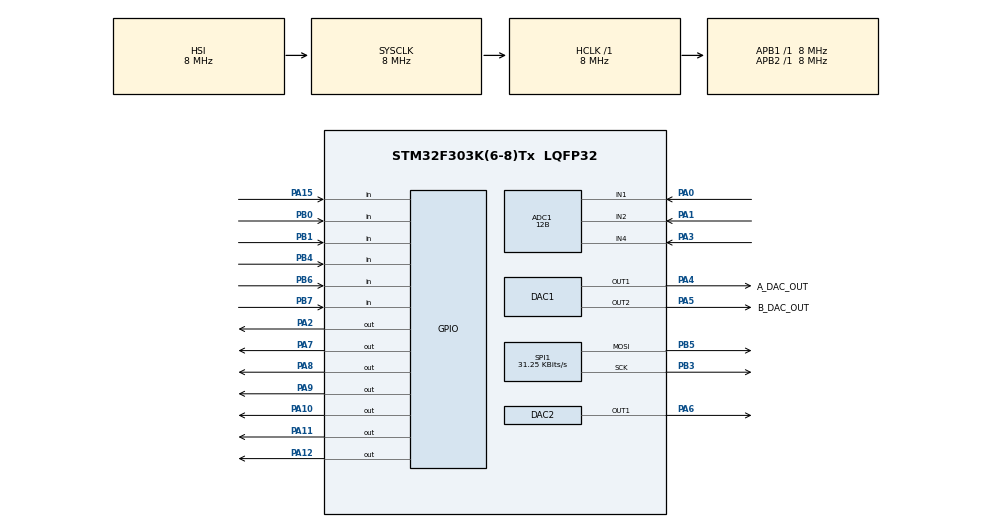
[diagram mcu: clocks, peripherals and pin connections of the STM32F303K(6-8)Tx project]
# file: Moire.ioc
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ADC1.Channel-17\#ChannelRegularConversion=ADC_CHANNEL_1
ADC1.Channel-18\#ChannelRegularConversion=ADC_CHANNEL_2
ADC1.Channel-19\#ChannelRegularConversion=ADC_CHANNEL_4
ADC1.Channel-21\#ChannelRegularConversion=ADC_CHANNEL_4
ADC1.ClockPrescaler=ADC_CLOCK_SYNC_PCLK_DIV4
ADC1.ContinuousConvMode=ENABLE
ADC1.DMAContinuousRequests=ENABLE
ADC1.DataAlign=ADC_DATAALIGN_RIGHT
ADC1.DiscontinuousConvMode=DISABLE
ADC1.EOCSelection=ADC_EOC_SEQ_CONV
ADC1.EnableAnalogWatchDog1=false
ADC1.EnableAnalogWatchDog2=false
ADC1.EnableAnalogWatchDog3=false
ADC1.EnableInjectedConversion=ENABLE
ADC1.EnableRegularConversion=ENABLE
ADC1.ExternalTrigConv=ADC_SOFTWARE_START
ADC1.ExternalTrigConvEdge=ADC_EXTERNALTRIGCONVEDGE_NONE
ADC1.InjNumberOfConversion=0
ADC1.LowPowerAutoWait=DISABLE
ADC1.NbrOfConversion=4
ADC1.NbrOfConversionFlag=1
ADC1.Offset-17\#ChannelRegularConversion=0
ADC1.Offset-18\#ChannelRegularConversion=0
ADC1.Offset-19\#ChannelRegularConversion=0
ADC1.Offset-21\#ChannelRegularConversion=0
ADC1.OffsetNumber-17\#ChannelRegularConversion=ADC_OFFSET_NONE
ADC1.OffsetNumber-18\#ChannelRegularConversion=ADC_OFFSET_NONE
ADC1.OffsetNumber-19\#ChannelRegularConversion=ADC_OFFSET_NONE
ADC1.OffsetNumber-21\#ChannelRegularConversion=ADC_OFFSET_NONE
ADC1.Overrun=ADC_OVR_DATA_OVERWRITTEN
ADC1.Rank-17\#ChannelRegularConversion=1
ADC1.Rank-18\#ChannelRegularConversion=2
ADC1.Rank-19\#ChannelRegularConversion=3
ADC1.Rank-21\#ChannelRegularConversion=4
ADC1.Resolution=ADC_RESOLUTION_12B
ADC1.SamplingTime-17\#ChannelRegularConversion=ADC_SAMPLETIME_1CYCLE_5
ADC1.SamplingTime-18\#ChannelRegularConversion=ADC_SAMPLETIME_1CYCLE_5
ADC1.SamplingTime-19\#ChannelRegularConversion=ADC_SAMPLETIME_1CYCLE_5
ADC1.SamplingTime-21\#ChannelRegularConversion=ADC_SAMPLETIME_1CYCLE_5
ADC1.ScanConvMode=ADC_SCAN_ENABLE
ADC1.SubFamily=STM32F303x8
ADC1.master=1
DAC1.DAC_OutputBuffer=DAC_OUTPUTBUFFER_ENABLE
DAC1.DAC_Trigger=DAC_TRIGGER_NONE
Dma.ADC1.1.Direction=DMA_PERIPH_TO_MEMORY
Dma.ADC1.1.Instance=DMA1_Channel1
Dma.ADC1.1.MemDataAlignment=DMA_MDATAALIGN_WORD
Dma.ADC1.1.MemInc=DMA_MINC_ENABLE
Dma.ADC1.1.Mode=DMA_CIRCULAR
Dma.ADC1.1.PeriphDataAlignment=DMA_PDATAALIGN_WORD
Dma.ADC1.1.PeriphInc=DMA_PINC_DISABLE
Dma.ADC1.1.Priority=DMA_PRIORITY_LOW
Dma.DAC1_CH1.0.Direction=DMA_MEMORY_TO_PERIPH
Dma.DAC1_CH1.0.Instance=DMA1_Channel3
Dma.DAC1_CH1.0.MemDataAlignment=DMA_MDATAALIGN_HALFWORD
Dma.DAC1_CH1.0.MemInc=DMA_MINC_ENABLE
Dma.DAC1_CH1.0.Mode=DMA_CIRCULAR
Dma.DAC1_CH1.0.PeriphDataAlignment=DMA_PDATAALIGN_HALFWORD
Dma.DAC1_CH1.0.PeriphInc=DMA_PINC_DISABLE
Dma.DAC1_CH1.0.Priority=DMA_PRIORITY_HIGH
Dma.Request0=DAC1_CH1
Dma.Request1=ADC1
Mcu.Family=STM32F3
Mcu.Name=STM32F303K(6-8)Tx
Mcu.Package=LQFP32
NVIC.ADC1_2_IRQn=true\:0\:0\:false\:false\:true\:true
NVIC.DMA1_Channel1_IRQn=true\:0\:0\:false\:false\:true\:false
NVIC.DMA1_Channel3_IRQn=true\:0\:0\:false\:false\:true\:false
NVIC.PriorityGroup=NVIC_PRIORITYGROUP_4
NVIC.TIM2_IRQn=true\:0\:0\:false\:false\:true\:true
NVIC.TIM6_DAC1_IRQn=true\:0\:0\:false\:false\:true\:true
PA0.Mode=IN1-Single-Ended
PA0.Signal=ADC1_IN1
PA1.Mode=IN2-Single-Ended
PA1.Signal=ADC1_IN2
PA10.Signal=GPIO_Output
PA11.Signal=GPIO_Output
PA12.Signal=GPIO_Output
PA13.GPIO_Label=SWDIO
PA13.Signal=SYS_JTMS-SWDIO
PA14.Signal=SYS_JTCK-SWCLK
PA15.GPIO_PuPd=GPIO_PULLUP
PA15.Signal=GPIO_Input
PA2.Signal=GPIO_Output
PA3.Mode=IN4-Single-Ended
PA3.Signal=ADC1_IN4
PA4.GPIO_Label=A_DAC_OUT
PA4.Signal=COMP_DAC11_group
PA5.GPIO_Label=B_DAC_OUT
PA5.Signal=COMP_DAC12_group
PA6.Signal=COMP_DAC21_group
PA7.Signal=GPIO_Output
PA8.Signal=GPIO_Output
PA9.GPIO_Speed=GPIO_SPEED_FREQ_HIGH
PA9.PinState=GPIO_PIN_RESET
PA9.Signal=GPIO_Output
PB0.GPIO_PuPd=GPIO_PULLUP
PB0.Signal=GPIO_Input
PB1.GPIO_PuPd=GPIO_PULLUP
PB1.Signal=GPIO_Input
PB3.Mode=TX_Only_Simplex_Unidirect_Master
PB3.Signal=SPI1_SCK
PB4.GPIO_PuPd=GPIO_PULLUP
PB4.Signal=GPIO_Input
PB5.Mode=TX_Only_Simplex_Unidirect_Master
PB5.Signal=SPI1_MOSI
PB6.GPIO_PuPd=GPIO_PULLUP
PB6.Signal=GPIO_Input
PB7.GPIO_PuPd=GPIO_PULLUP
PB7.Signal=GPIO_Input
PF0\ /\ OSC_IN.Mode=HSE-External-Oscillator
PF0\ /\ OSC_IN.Signal=RCC_OSC_IN
PF1\ /\ OSC_OUT.Mode=HSE-External-Oscillator
PF1\ /\ OSC_OUT.Signal=RCC_OSC_OUT
ProjectManager.HeapSize=0x200
ProjectManager.StackSize=0x400
ProjectManager.TargetToolchain=Makefile
RCC.AHBFreq_Value=8000000
RCC.APB1Freq_Value=8000000
RCC.APB2Freq_Value=8000000
RCC.CortexFreq_Value=8000000
RCC.HSE_VALUE=8000000
RCC.HSI_VALUE=8000000
RCC.PLLMUL=RCC_PLL_MUL4
RCC.SYSCLKFreq_VALUE=8000000
SH.COMP_DAC11_group.0=DAC1_OUT1,DAC_OUT1
SH.COMP_DAC12_group.0=DAC1_OUT2,DAC_OUT2
SH.COMP_DAC21_group.0=DAC2_OUT1,Switch_Enable_OUT1
SPI1.BaudRatePrescaler=SPI_BAUDRATEPRESCALER_256
SPI1.CLKPolarity=SPI_POLARITY_LOW
SPI1.CalculateBaudRate=31.25 KBits/s
SPI1.DataSize=SPI_DATASIZE_16BIT
SPI1.Direction=SPI_DIRECTION_2LINES
SPI1.Mode=SPI_MODE_MASTER
SPI1.NSSPMode=SPI_NSS_PULSE_ENABLE
SPI1.VirtualType=VM_MASTER
TIM2.Period=4608
TIM2.Prescaler=1
TIM6.Period=1
TIM6.Prescaler=1
TIM6.TIM_MasterOutputTrigger=TIM_TRGO_UPDATE
VP_TIM2_VS_ClockSourceINT.Mode=Internal
VP_TIM6_VS_ClockSourceINT.Mode=Enable_Timer
VP_TIM7_VS_ClockSourceINT.Mode=Enable_Timer
board=NUCLEO-F303K8

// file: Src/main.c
/**
  ******************************************************************************
  * @file           : main.c
  * @brief          : Main program body
  ******************************************************************************
  ** This notice applies to any and all portions of this file
  * that are not between comment pairs USER CODE BEGIN and
  * USER CODE END. Other portions of this file, whether
  * inserted by the user or by software development tools
  * are owned by their respective copyright owners.
  *
  * COPYRIGHT(c) 2018 STMicroelectronics
  *
  * Redistribution and use in source and binary forms, with or without modification,
  * are permitted provided that the following conditions are met:
  *   1. Redistributions of source code must retain the above copyright notice,
  *      this list of conditions and the following disclaimer.
  *   2. Redistributions in binary form must reproduce the above copyright notice,
  *      this list of conditions and the following disclaimer in the documentation
  *      and/or other materials provided with the distribution.
  *   3. Neither the name of STMicroelectronics nor the names of its contributors
  *      may be used to endorse or promote products derived from this software
  *      without specific prior written permission.
  *
  * THIS SOFTWARE IS PROVIDED BY THE COPYRIGHT HOLDERS AND CONTRIBUTORS "AS IS"
  * AND ANY EXPRESS OR IMPLIED WARRANTIES, INCLUDING, BUT NOT LIMITED TO, THE
  * IMPLIED WARRANTIES OF MERCHANTABILITY AND FITNESS FOR A PARTICULAR PURPOSE ARE
  * DISCLAIMED. IN NO EVENT SHALL THE COPYRIGHT HOLDER OR CONTRIBUTORS BE LIABLE
  * FOR ANY DIRECT, INDIRECT, INCIDENTAL, SPECIAL, EXEMPLARY, OR CONSEQUENTIAL
  * DAMAGES (INCLUDING, BUT NOT LIMITED TO, PROCUREMENT OF SUBSTITUTE GOODS OR
  * SERVICES; LOSS OF USE, DATA, OR PROFITS; OR BUSINESS INTERRUPTION) HOWEVER
  * CAUSED AND ON ANY THEORY OF LIABILITY, WHETHER IN CONTRACT, STRICT LIABILITY,
  * OR TORT (INCLUDING NEGLIGENCE OR OTHERWISE) ARISING IN ANY WAY OUT OF THE USE
  * OF THIS SOFTWARE, EVEN IF ADVISED OF THE POSSIBILITY OF SUCH DAMAGE.
  *
  ******************************************************************************
  */
#include "main.h"
#include "stm32f3xx_hal.h"
#include "adc.h"
#include "dac.h"
#include "dma.h"
#include "spi.h"
#include "tim.h"
#include "gpio.h"

/* USER CODE BEGIN Includes */
#include "moire.h"

/* USER CODE END Includes */

/* USER CODE BEGIN PV */
/* Private variables ---------------------------------------------------------*/
Moire moire_sys;

/* USER CODE END PV */

void SystemClock_Config(void);

/* USER CODE BEGIN PFP */
/* Private function prototypes -----------------------------------------------*/

/* USER CODE END PFP */

int main(void)
{

  /* MCU Configuration----------------------------------------------------------*/

  /* Reset of all peripherals, Initializes the Flash interface and the Systick. */
  HAL_Init();

  /* Configure the system clock */
  SystemClock_Config();

  /* Initialize all configured peripherals */
  MX_GPIO_Init();
  MX_DMA_Init();
  MX_DAC1_Init();
  MX_TIM6_Init();
  MX_ADC1_Init();
  MX_DAC2_Init();
  MX_TIM7_Init();
  MX_TIM2_Init();
  MX_SPI1_Init();
  /* USER CODE BEGIN 2 */
  HAL_DAC_Start(&hdac1, DAC_CHANNEL_1);
  HAL_DAC_Start(&hdac1, DAC_CHANNEL_2);
  HAL_DAC_Start(&hdac2, DAC_CHANNEL_1);

  moire_sys.Init();
  HAL_TIM_Base_Start_IT(&htim2);

  /* USER CODE END 2 */

  /* Infinite loop */
  /* USER CODE BEGIN WHILE */
  while (1)
  {
    moire_sys.Update();
  /* USER CODE END WHILE */

  }

}

void SystemClock_Config(void)
{

  RCC_OscInitTypeDef RCC_OscInitStruct;
  RCC_ClkInitTypeDef RCC_ClkInitStruct;

    /**Initializes the CPU, AHB and APB busses clocks
    */
  RCC_OscInitStruct.OscillatorType = RCC_OSCILLATORTYPE_HSI;
  RCC_OscInitStruct.HSIState = RCC_HSI_ON;
  RCC_OscInitStruct.HSICalibrationValue = 16;
  RCC_OscInitStruct.PLL.PLLState = RCC_PLL_NONE;
  if (HAL_RCC_OscConfig(&RCC_OscInitStruct) != HAL_OK)
  {
    _Error_Handler(__FILE__, __LINE__);
  }

    /**Initializes the CPU, AHB and APB busses clocks
    */
  RCC_ClkInitStruct.ClockType = RCC_CLOCKTYPE_HCLK|RCC_CLOCKTYPE_SYSCLK
                              |RCC_CLOCKTYPE_PCLK1|RCC_CLOCKTYPE_PCLK2;
  RCC_ClkInitStruct.SYSCLKSource = RCC_SYSCLKSOURCE_HSI;
  RCC_ClkInitStruct.AHBCLKDivider = RCC_SYSCLK_DIV1;
  RCC_ClkInitStruct.APB1CLKDivider = RCC_HCLK_DIV1;
  RCC_ClkInitStruct.APB2CLKDivider = RCC_HCLK_DIV1;

  if (HAL_RCC_ClockConfig(&RCC_ClkInitStruct, FLASH_LATENCY_0) != HAL_OK)
  {
    _Error_Handler(__FILE__, __LINE__);
  }

    /**Configure the Systick interrupt time
    */
  HAL_SYSTICK_Config(HAL_RCC_GetHCLKFreq()/1000);

    /**Configure the Systick
    */
  HAL_SYSTICK_CLKSourceConfig(SYSTICK_CLKSOURCE_HCLK);

  /* SysTick_IRQn interrupt configuration */
  HAL_NVIC_SetPriority(SysTick_IRQn, 0, 0);
}

/* USER CODE BEGIN 4 */
void HAL_TIM_PeriodElapsedCallback(TIM_HandleTypeDef *htim)
{
  if (htim->Instance == TIM2)
  {
    moire_sys.tick = 1;
  }
}
/* USER CODE END 4 */

void _Error_Handler(char *file, int line)
{
  while (1)
  {
  }
}

/************************ (C) COPYRIGHT STMicroelectronics *****END OF FILE****/
